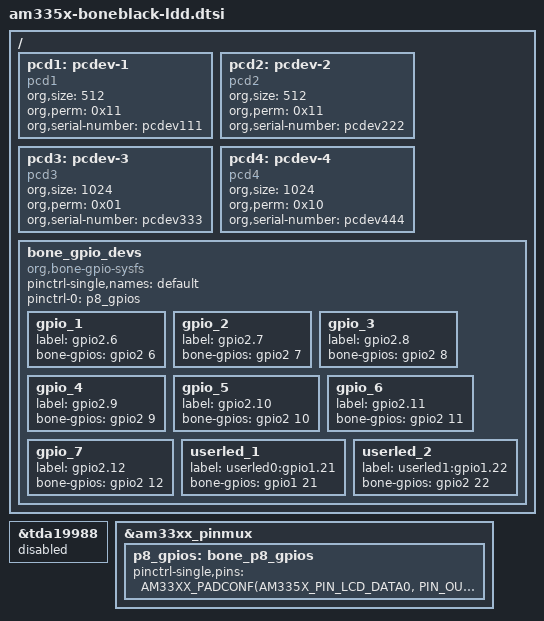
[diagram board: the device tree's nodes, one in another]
/ {
	pcd1: pcdev-1 {
		compatible = "pcd1";
		org,size = <512>;
		org,perm = <0x11>;
		org,serial-number = "pcdev111";
	};
	pcd2: pcdev-2 {
		compatible = "pcd2";
		org,size = <512>;
		org,perm = <0x11>;
		org,serial-number = "pcdev222";
	};
	pcd3: pcdev-3 {
		compatible = "pcd3";
		org,size = <1024>;
		org,perm = <0x01>;
		org,serial-number = "pcdev333";
	};
	pcd4: pcdev-4 {
		compatible = "pcd4";
		org,size = <1024>;
		org,perm = <0x10>;
		org,serial-number = "pcdev444";
	};
	
	bone_gpio_devs {
		compatible = "org,bone-gpio-sysfs";
		pinctrl-single,names = "default";
		pinctrl-0 = <&p8_gpios>;

		gpio_1 {
			label = "gpio2.6";
			bone-gpios = <&gpio2 6 GPIO_ACTIVE_HIGH>;
		};
		gpio_2 {
			label = "gpio2.7";
			bone-gpios = <&gpio2 7 GPIO_ACTIVE_HIGH>;
		};
		gpio_3 {
			label = "gpio2.8";
			bone-gpios = <&gpio2 8 GPIO_ACTIVE_HIGH>;
		};
		gpio_4 {
			label = "gpio2.9";
			bone-gpios = <&gpio2 9 GPIO_ACTIVE_HIGH>;
		};
		gpio_5 {
			label = "gpio2.10";
			bone-gpios = <&gpio2 10 GPIO_ACTIVE_HIGH>;
		};
		gpio_6 {
			label = "gpio2.11";
			bone-gpios = <&gpio2 11 GPIO_ACTIVE_HIGH>;
		};
		gpio_7 {
			label = "gpio2.12";
			bone-gpios = <&gpio2 12 GPIO_ACTIVE_HIGH>;
		};
		userled_1{
			label = "userled0:gpio1.21";
			bone-gpios = <&gpio1 21 GPIO_ACTIVE_HIGH>;
		};
		userled_2 {
			label = "userled1:gpio1.22";
			bone-gpios = <&gpio2 22 GPIO_ACTIVE_HIGH>;
		};
	};
};

&tda19988 {
	status = "disabled";
};

&am33xx_pinmux {
	p8_gpios: bone_p8_gpios {
		pinctrl-single,pins = <
			AM33XX_PADCONF(AM335X_PIN_LCD_DATA0, PIN_OUTPUT, MUX_MODE7)
			AM33XX_PADCONF(AM335X_PIN_LCD_DATA1, PIN_OUTPUT, MUX_MODE7)
			AM33XX_PADCONF(AM335X_PIN_LCD_DATA2, PIN_OUTPUT, MUX_MODE7)
			AM33XX_PADCONF(AM335X_PIN_LCD_DATA3, PIN_OUTPUT, MUX_MODE7)
			AM33XX_PADCONF(AM335X_PIN_LCD_DATA4, PIN_OUTPUT, MUX_MODE7)
			AM33XX_PADCONF(AM335X_PIN_LCD_DATA5, PIN_OUTPUT, MUX_MODE7)
			AM33XX_PADCONF(AM335X_PIN_LCD_DATA6, PIN_OUTPUT, MUX_MODE7)
		>;
	};
};

